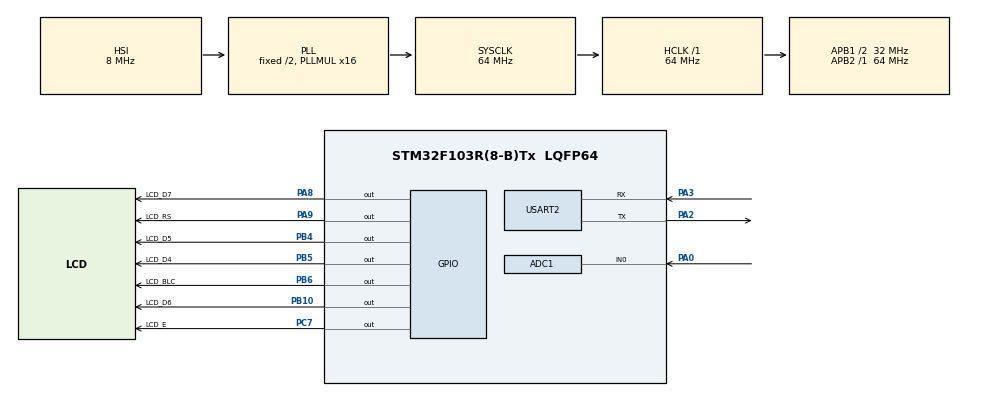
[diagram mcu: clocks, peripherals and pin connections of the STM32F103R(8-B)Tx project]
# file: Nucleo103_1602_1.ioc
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ADC1.Channel-0\#ChannelRegularConversion=ADC_CHANNEL_0
ADC1.NbrOfConversionFlag=1
ADC1.Rank-0\#ChannelRegularConversion=1
ADC1.SamplingTime-0\#ChannelRegularConversion=ADC_SAMPLETIME_1CYCLE_5
ADC1.master=1
Mcu.Family=STM32F1
Mcu.Name=STM32F103R(8-B)Tx
Mcu.Package=LQFP64
NVIC.PriorityGroup=NVIC_PRIORITYGROUP_4
PA0-WKUP.Signal=ADCx_IN0
PA13.Mode=Trace_Asynchronous_SW
PA13.Signal=SYS_JTMS-SWDIO
PA14.Mode=Trace_Asynchronous_SW
PA14.Signal=SYS_JTCK-SWCLK
PA2.Mode=Asynchronous
PA2.Signal=USART2_TX
PA3.Mode=Asynchronous
PA3.Signal=USART2_RX
PA8.GPIO_Label=LCD_D7
PA8.Signal=GPIO_Output
PA9.GPIO_Label=LCD_RS
PA9.Signal=GPIO_Output
PB10.GPIO_Label=LCD_D6
PB10.Signal=GPIO_Output
PB3.Mode=Trace_Asynchronous_SW
PB3.Signal=SYS_JTDO-TRACESWO
PB4.GPIO_Label=LCD_D5
PB4.Signal=GPIO_Output
PB5.GPIO_Label=LCD_D4
PB5.Signal=GPIO_Output
PB6.GPIO_Label=LCD_BLC
PB6.Signal=GPIO_Output
PB8.Signal=I2C1_SCL
PB9.Signal=I2C1_SDA
PC14-OSC32_IN.Mode=LSE-External-Oscillator
PC14-OSC32_IN.Signal=RCC_OSC32_IN
PC15-OSC32_OUT.Mode=LSE-External-Oscillator
PC15-OSC32_OUT.Signal=RCC_OSC32_OUT
PC7.GPIO_Label=LCD_E
PC7.Signal=GPIO_Output
ProjectManager.HeapSize=0x200
ProjectManager.StackSize=0x400
ProjectManager.TargetToolchain=TrueSTUDIO
RCC.ADCPresc=RCC_ADCPCLK2_DIV6
RCC.AHBFreq_Value=64000000
RCC.APB1CLKDivider=RCC_HCLK_DIV2
RCC.APB1Freq_Value=32000000
RCC.APB1TimFreq_Value=64000000
RCC.APB2Freq_Value=64000000
RCC.APB2TimFreq_Value=64000000
RCC.HCLKFreq_Value=64000000
RCC.PLLMUL=RCC_PLL_MUL16
RCC.SYSCLKFreq_VALUE=64000000
RCC.SYSCLKSource=RCC_SYSCLKSOURCE_PLLCLK
RCC.USBFreq_Value=64000000
SH.ADCx_IN0.0=ADC1_IN0,IN0
USART2.VirtualMode=VM_ASYNC
board=custom

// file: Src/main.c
/* USER CODE BEGIN Header */
/**
  ******************************************************************************
  * @file           : main.c
  * @brief          : Main program body
  ******************************************************************************
  * @attention
  *
  * <h2><center>&copy; Copyright (c) 2020 STMicroelectronics.
  * All rights reserved.</center></h2>
  *
  * This software component is licensed by ST under BSD 3-Clause license,
  * the "License"; You may not use this file except in compliance with the
  * License. You may obtain a copy of the License at:
  *                        opensource.org/licenses/BSD-3-Clause
  *
  ******************************************************************************
  */
/* USER CODE END Header */

#include "main.h"

/* USER CODE BEGIN Includes */
#include <stdio.h>
#include "lcd.h"
/* USER CODE END Includes */

ADC_HandleTypeDef hadc1;

UART_HandleTypeDef huart2;

void SystemClock_Config(void);
static void MX_GPIO_Init(void);
static void MX_ADC1_Init(void);
static void MX_USART2_UART_Init(void);

/* USER CODE BEGIN 0 */
int _write(int file, char *ptr, int len)
{

  HAL_UART_Transmit(&huart2, (uint8_t*)ptr, (uint16_t)len, 0xFFFFFFFF);

  return len;
}
/* USER CODE END 0 */

int main(void)
{
  /* USER CODE BEGIN 1 */
	uint8_t count1=0;
  /* USER CODE END 1 */

  /* MCU Configuration--------------------------------------------------------*/

  /* Reset of all peripherals, Initializes the Flash interface and the Systick. */
  HAL_Init();

  /* Configure the system clock */
  SystemClock_Config();

  /* Initialize all configured peripherals */
  MX_GPIO_Init();
  MX_ADC1_Init();
  MX_USART2_UART_Init();
  /* USER CODE BEGIN 2 */
  DispInit(2, 16);

  DispStr(0, 0, (char *)"STM32F103");
  //DispStr(1, 0, (char *)"Nucleo-64");
  /* USER CODE END 2 */

  /* Infinite loop */
  while (1)
  {

    /* USER CODE BEGIN 3 */
  	//HAL_GPIO_TogglePin(LCD_BLC_GPIO_Port, LCD_BLC_Pin);							// LCD Backlight Control Toggle
  	HAL_GPIO_WritePin(LCD_BLC_GPIO_Port, LCD_BLC_Pin, GPIO_PIN_SET);	// LCD Backlight Control On
  	printf("Count Value %d \r \n", count1++);
  	HAL_Delay(1000);
  }
  /* USER CODE END 3 */
}

void SystemClock_Config(void)
{
  RCC_OscInitTypeDef RCC_OscInitStruct = {0};
  RCC_ClkInitTypeDef RCC_ClkInitStruct = {0};
  RCC_PeriphCLKInitTypeDef PeriphClkInit = {0};

  /** Initializes the CPU, AHB and APB busses clocks
  */
  RCC_OscInitStruct.OscillatorType = RCC_OSCILLATORTYPE_HSI;
  RCC_OscInitStruct.HSIState = RCC_HSI_ON;
  RCC_OscInitStruct.HSICalibrationValue = RCC_HSICALIBRATION_DEFAULT;
  RCC_OscInitStruct.PLL.PLLState = RCC_PLL_ON;
  RCC_OscInitStruct.PLL.PLLSource = RCC_PLLSOURCE_HSI_DIV2;
  RCC_OscInitStruct.PLL.PLLMUL = RCC_PLL_MUL16;
  if (HAL_RCC_OscConfig(&RCC_OscInitStruct) != HAL_OK)
  {
    Error_Handler();
  }
  /** Initializes the CPU, AHB and APB busses clocks
  */
  RCC_ClkInitStruct.ClockType = RCC_CLOCKTYPE_HCLK|RCC_CLOCKTYPE_SYSCLK
                              |RCC_CLOCKTYPE_PCLK1|RCC_CLOCKTYPE_PCLK2;
  RCC_ClkInitStruct.SYSCLKSource = RCC_SYSCLKSOURCE_PLLCLK;
  RCC_ClkInitStruct.AHBCLKDivider = RCC_SYSCLK_DIV1;
  RCC_ClkInitStruct.APB1CLKDivider = RCC_HCLK_DIV2;
  RCC_ClkInitStruct.APB2CLKDivider = RCC_HCLK_DIV1;

  if (HAL_RCC_ClockConfig(&RCC_ClkInitStruct, FLASH_LATENCY_2) != HAL_OK)
  {
    Error_Handler();
  }
  PeriphClkInit.PeriphClockSelection = RCC_PERIPHCLK_ADC;
  PeriphClkInit.AdcClockSelection = RCC_ADCPCLK2_DIV6;
  if (HAL_RCCEx_PeriphCLKConfig(&PeriphClkInit) != HAL_OK)
  {
    Error_Handler();
  }
}

static void MX_ADC1_Init(void)
{

  ADC_ChannelConfTypeDef sConfig = {0};

  /** Common config
  */
  hadc1.Instance = ADC1;
  hadc1.Init.ScanConvMode = ADC_SCAN_DISABLE;
  hadc1.Init.ContinuousConvMode = DISABLE;
  hadc1.Init.DiscontinuousConvMode = DISABLE;
  hadc1.Init.ExternalTrigConv = ADC_SOFTWARE_START;
  hadc1.Init.DataAlign = ADC_DATAALIGN_RIGHT;
  hadc1.Init.NbrOfConversion = 1;
  if (HAL_ADC_Init(&hadc1) != HAL_OK)
  {
    Error_Handler();
  }
  /** Configure Regular Channel
  */
  sConfig.Channel = ADC_CHANNEL_0;
  sConfig.Rank = ADC_REGULAR_RANK_1;
  sConfig.SamplingTime = ADC_SAMPLETIME_1CYCLE_5;
  if (HAL_ADC_ConfigChannel(&hadc1, &sConfig) != HAL_OK)
  {
    Error_Handler();
  }

}

static void MX_USART2_UART_Init(void)
{

  huart2.Instance = USART2;
  huart2.Init.BaudRate = 115200;
  huart2.Init.WordLength = UART_WORDLENGTH_8B;
  huart2.Init.StopBits = UART_STOPBITS_1;
  huart2.Init.Parity = UART_PARITY_NONE;
  huart2.Init.Mode = UART_MODE_TX_RX;
  huart2.Init.HwFlowCtl = UART_HWCONTROL_NONE;
  huart2.Init.OverSampling = UART_OVERSAMPLING_16;
  if (HAL_UART_Init(&huart2) != HAL_OK)
  {
    Error_Handler();
  }

}

static void MX_GPIO_Init(void)
{
  GPIO_InitTypeDef GPIO_InitStruct = {0};

  /* GPIO Ports Clock Enable */
  __HAL_RCC_GPIOC_CLK_ENABLE();
  __HAL_RCC_GPIOA_CLK_ENABLE();
  __HAL_RCC_GPIOB_CLK_ENABLE();

  /*Configure GPIO pin Output Level */
  HAL_GPIO_WritePin(GPIOB, LCD_D6_Pin|LCD_D5_Pin|LCD_D4_Pin|LCD_BLC_Pin, GPIO_PIN_RESET);

  /*Configure GPIO pin Output Level */
  HAL_GPIO_WritePin(LCD_E_GPIO_Port, LCD_E_Pin, GPIO_PIN_RESET);

  /*Configure GPIO pin Output Level */
  HAL_GPIO_WritePin(GPIOA, LCD_D7_Pin|LCD_RS_Pin, GPIO_PIN_RESET);

  /*Configure GPIO pins : LCD_D6_Pin LCD_D5_Pin LCD_D4_Pin LCD_BLC_Pin */
  GPIO_InitStruct.Pin = LCD_D6_Pin|LCD_D5_Pin|LCD_D4_Pin|LCD_BLC_Pin;
  GPIO_InitStruct.Mode = GPIO_MODE_OUTPUT_PP;
  GPIO_InitStruct.Pull = GPIO_NOPULL;
  GPIO_InitStruct.Speed = GPIO_SPEED_FREQ_LOW;
  HAL_GPIO_Init(GPIOB, &GPIO_InitStruct);

  /*Configure GPIO pin : LCD_E_Pin */
  GPIO_InitStruct.Pin = LCD_E_Pin;
  GPIO_InitStruct.Mode = GPIO_MODE_OUTPUT_PP;
  GPIO_InitStruct.Pull = GPIO_NOPULL;
  GPIO_InitStruct.Speed = GPIO_SPEED_FREQ_LOW;
  HAL_GPIO_Init(LCD_E_GPIO_Port, &GPIO_InitStruct);

  /*Configure GPIO pins : LCD_D7_Pin LCD_RS_Pin */
  GPIO_InitStruct.Pin = LCD_D7_Pin|LCD_RS_Pin;
  GPIO_InitStruct.Mode = GPIO_MODE_OUTPUT_PP;
  GPIO_InitStruct.Pull = GPIO_NOPULL;
  GPIO_InitStruct.Speed = GPIO_SPEED_FREQ_LOW;
  HAL_GPIO_Init(GPIOA, &GPIO_InitStruct);

  /*Configure GPIO pins : PB8 PB9 */
  GPIO_InitStruct.Pin = GPIO_PIN_8|GPIO_PIN_9;
  GPIO_InitStruct.Mode = GPIO_MODE_AF_OD;
  GPIO_InitStruct.Speed = GPIO_SPEED_FREQ_HIGH;
  HAL_GPIO_Init(GPIOB, &GPIO_InitStruct);

  /*Configure peripheral I/O remapping */
  __HAL_AFIO_REMAP_I2C1_ENABLE();

}

void Error_Handler(void)
{
}

/************************ (C) COPYRIGHT STMicroelectronics *****END OF FILE****/
